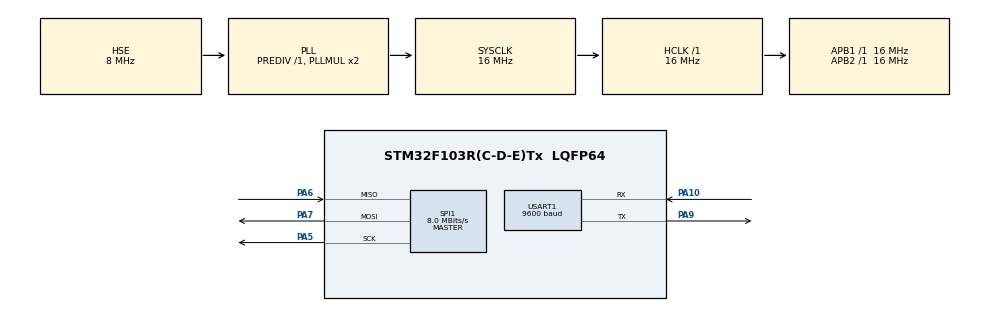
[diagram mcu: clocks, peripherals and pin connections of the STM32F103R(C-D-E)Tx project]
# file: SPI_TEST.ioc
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Mcu.Family=STM32F1
Mcu.Name=STM32F103R(C-D-E)Tx
Mcu.Package=LQFP64
NVIC.PriorityGroup=NVIC_PRIORITYGROUP_4
PA10.Mode=Asynchronous
PA10.Signal=USART1_RX
PA5.Mode=Full_Duplex_Master
PA5.Signal=SPI1_SCK
PA6.Mode=Full_Duplex_Master
PA6.Signal=SPI1_MISO
PA7.Mode=Full_Duplex_Master
PA7.Signal=SPI1_MOSI
PA9.Mode=Asynchronous
PA9.Signal=USART1_TX
PD0-OSC_IN.Mode=HSE-External-Oscillator
PD0-OSC_IN.Signal=RCC_OSC_IN
PD1-OSC_OUT.Mode=HSE-External-Oscillator
PD1-OSC_OUT.Signal=RCC_OSC_OUT
ProjectManager.HeapSize=0x200
ProjectManager.StackSize=0x400
ProjectManager.TargetToolchain=MDK-ARM V5.27
RCC.AHBFreq_Value=16000000
RCC.APB1Freq_Value=16000000
RCC.APB1TimFreq_Value=16000000
RCC.APB2Freq_Value=16000000
RCC.APB2TimFreq_Value=16000000
RCC.HCLKFreq_Value=16000000
RCC.PLLSourceVirtual=RCC_PLLSOURCE_HSE
RCC.SYSCLKFreq_VALUE=16000000
RCC.SYSCLKSource=RCC_SYSCLKSOURCE_PLLCLK
RCC.USBFreq_Value=16000000
SPI1.CalculateBaudRate=8.0 MBits/s
SPI1.Direction=SPI_DIRECTION_2LINES
SPI1.Mode=SPI_MODE_MASTER
SPI1.VirtualType=VM_MASTER
USART1.BaudRate=9600
USART1.VirtualMode=VM_ASYNC
VP_SYS_VS_ND.Mode=No_Debug
board=custom

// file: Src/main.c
/* USER CODE BEGIN Header */
/**
  ******************************************************************************
  * @file           : main.c
  * @brief          : Main program body
  ******************************************************************************
  * @attention
  *
  * <h2><center>&copy; Copyright (c) 2020 STMicroelectronics.
  * All rights reserved.</center></h2>
  *
  * This software component is licensed by ST under BSD 3-Clause license,
  * the "License"; You may not use this file except in compliance with the
  * License. You may obtain a copy of the License at:
  *                        opensource.org/licenses/BSD-3-Clause
  *
  ******************************************************************************
  */
/* USER CODE END Header */

#include "main.h"
#include "spi.h"
#include "usart.h"
#include "gpio.h"

void SystemClock_Config(void);

/* USER CODE BEGIN 0 */
#include "stdio.h"
/* USER CODE END 0 */

int main(void)
{
  /* USER CODE BEGIN 1 */
	uint8_t t[2] ;
	uint8_t r[2]  ;
  /* USER CODE END 1 */

  /* MCU Configuration--------------------------------------------------------*/

  /* Reset of all peripherals, Initializes the Flash interface and the Systick. */
  HAL_Init();

  /* Configure the system clock */
  SystemClock_Config();

  /* Initialize all configured peripherals */
  MX_GPIO_Init();
  MX_SPI1_Init();
  MX_USART1_UART_Init();

  /* Infinite loop */
  /* USER CODE BEGIN WHILE */
  while (1)
  {
//		t = 0xee;
//		r = 0xaa;
//		HAL_SPI_Transmit(&hspi1,&t,1,100);
//	//	printf("first:t=0x%x,r=0x%x\r\n",t,r);
//		HAL_SPI_Transmit(&hspi1,&r,1,100);
//		printf("second:t=0x%x,r=0x%x\r\n",t,r);
		t[0]=0xaa;
		t[1]=0xbb;
		r[0]=0xcc;
		r[1]=0xdd;
		HAL_SPI_TransmitReceive(&hspi1,t,r,2,100);
		printf("third:t=0x%x,0x%x,r=0x%x,0x%x\r\n\r\n",t[0],t[1],r[0],r[1]);
		HAL_Delay(2000);
    /* USER CODE END WHILE */

  }
}

void SystemClock_Config(void)
{
  RCC_OscInitTypeDef RCC_OscInitStruct = {0};
  RCC_ClkInitTypeDef RCC_ClkInitStruct = {0};

  /** Initializes the CPU, AHB and APB busses clocks
  */
  RCC_OscInitStruct.OscillatorType = RCC_OSCILLATORTYPE_HSE;
  RCC_OscInitStruct.HSEState = RCC_HSE_ON;
  RCC_OscInitStruct.HSEPredivValue = RCC_HSE_PREDIV_DIV1;
  RCC_OscInitStruct.HSIState = RCC_HSI_ON;
  RCC_OscInitStruct.PLL.PLLState = RCC_PLL_ON;
  RCC_OscInitStruct.PLL.PLLSource = RCC_PLLSOURCE_HSE;
  RCC_OscInitStruct.PLL.PLLMUL = RCC_PLL_MUL2;
  if (HAL_RCC_OscConfig(&RCC_OscInitStruct) != HAL_OK)
  {
    Error_Handler();
  }
  /** Initializes the CPU, AHB and APB busses clocks
  */
  RCC_ClkInitStruct.ClockType = RCC_CLOCKTYPE_HCLK|RCC_CLOCKTYPE_SYSCLK
                              |RCC_CLOCKTYPE_PCLK1|RCC_CLOCKTYPE_PCLK2;
  RCC_ClkInitStruct.SYSCLKSource = RCC_SYSCLKSOURCE_PLLCLK;
  RCC_ClkInitStruct.AHBCLKDivider = RCC_SYSCLK_DIV1;
  RCC_ClkInitStruct.APB1CLKDivider = RCC_HCLK_DIV1;
  RCC_ClkInitStruct.APB2CLKDivider = RCC_HCLK_DIV1;

  if (HAL_RCC_ClockConfig(&RCC_ClkInitStruct, FLASH_LATENCY_0) != HAL_OK)
  {
    Error_Handler();
  }
}

void Error_Handler(void)
{
}

/************************ (C) COPYRIGHT STMicroelectronics *****END OF FILE****/
